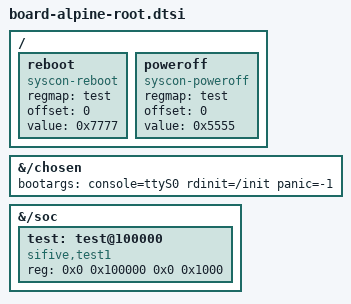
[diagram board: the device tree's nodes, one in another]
&{/chosen} {
    bootargs = "console=ttyS0 rdinit=/init panic=-1";
};

&{/soc} {
    test: test@100000 {
        compatible = "sifive,test1", "sifive,test0", "syscon";
        reg = <0x0 0x100000 0x0 0x1000>;
    };
};

/ {
    reboot {
        compatible = "syscon-reboot";
        regmap = <&test>;
        offset = <0>;
        value = <0x7777>;
    };

    poweroff {
        compatible = "syscon-poweroff";
        regmap = <&test>;
        offset = <0>;
        value = <0x5555>;
    };
};
